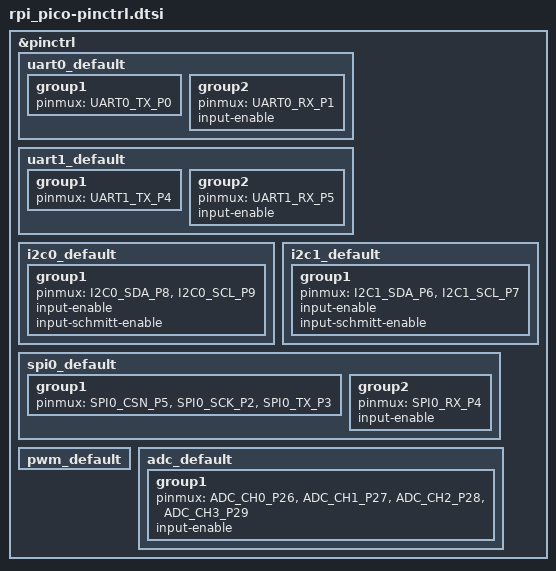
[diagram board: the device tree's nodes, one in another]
/*
 * Copyright (c) 2023 TiaC Systems
 * SPDX-License-Identifier: Apache-2.0
 */

&pinctrl {
	uart0_default: uart0_default {
		group1 {
			pinmux = <UART0_TX_P0>;
		};
		group2 {
			pinmux = <UART0_RX_P1>;
			input-enable;
		};
	};

	uart1_default: uart1_default {
		group1 {
			pinmux = <UART1_TX_P4>;
		};
		group2 {
			pinmux = <UART1_RX_P5>;
			input-enable;
		};
	};

	i2c0_default: i2c0_default {
		group1 {
			pinmux = <I2C0_SDA_P8>, <I2C0_SCL_P9>;
			input-enable;
			input-schmitt-enable;
		};
	};

	i2c1_default: i2c1_default {
		group1 {
			pinmux = <I2C1_SDA_P6>, <I2C1_SCL_P7>;
			input-enable;
			input-schmitt-enable;
		};
	};

	spi0_default: spi0_default {
		group1 {
			pinmux = <SPI0_CSN_P5>, <SPI0_SCK_P2>, <SPI0_TX_P3>;
		};
		group2 {
			pinmux = <SPI0_RX_P4>;
			input-enable;
		};
	};

	pwm_default: pwm_default {};

	adc_default: adc_default {
		group1 {
			pinmux = <ADC_CH0_P26>, <ADC_CH1_P27>,
				 <ADC_CH2_P28>, <ADC_CH3_P29>;
			input-enable;
		};
	};
};
